VERSION "fleet-can-dataset fcs2_profile_h v2.0 (SYNTHETIC, not OEM)"

NS_ :

BS_:

BU_: ABS BCM BMS CLU ECM EPS TCM

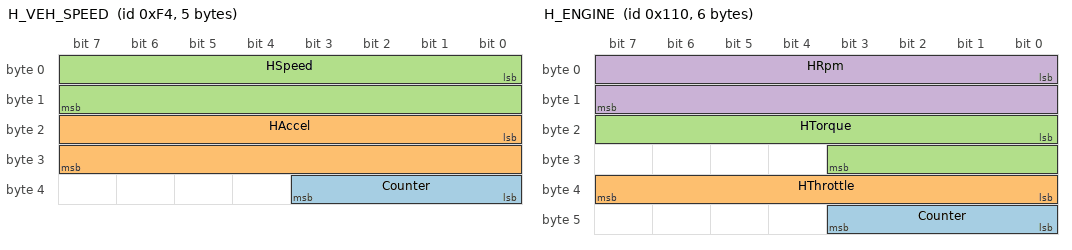
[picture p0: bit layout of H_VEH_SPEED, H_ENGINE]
BO_ 244 H_VEH_SPEED: 5 ABS
 SG_ Counter : 32|4@1+ (1,0) [0|15] "" Vector__XXX
 SG_ HAccel : 16|16@1- (0.001,0) [-32.768|32.767] "m/s^2" Vector__XXX
 SG_ HSpeed : 0|16@1+ (0.01,0) [0|655.35] "km/h" Vector__XXX

BO_ 272 H_ENGINE: 6 ECM
 SG_ Counter : 40|4@1+ (1,0) [0|15] "" Vector__XXX
 SG_ HThrottle : 32|8@1+ (0.4,0) [0|102] "%" Vector__XXX
 SG_ HTorque : 16|12@1+ (0.5,0) [0|2047.5] "Nm" Vector__XXX
 SG_ HRpm : 0|16@1+ (0.25,0) [0|16383.75] "rpm" Vector__XXX

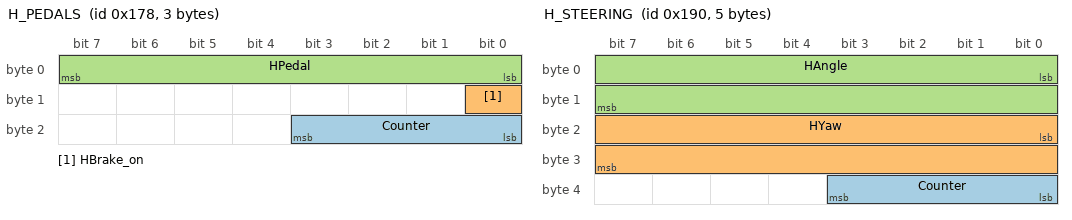
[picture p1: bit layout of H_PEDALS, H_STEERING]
BO_ 376 H_PEDALS: 3 ECM
 SG_ Counter : 16|4@1+ (1,0) [0|15] "" Vector__XXX
 SG_ HBrake_on : 8|1@1+ (1,0) [0|1] "" Vector__XXX
 SG_ HPedal : 0|8@1+ (0.4,0) [0|102] "%" Vector__XXX

BO_ 400 H_STEERING: 5 EPS
 SG_ Counter : 32|4@1+ (1,0) [0|15] "" Vector__XXX
 SG_ HYaw : 16|16@1- (0.01,0) [-327.68|327.67] "deg/s" Vector__XXX
 SG_ HAngle : 0|16@1- (0.1,0) [-3276.8|3276.7] "deg" Vector__XXX

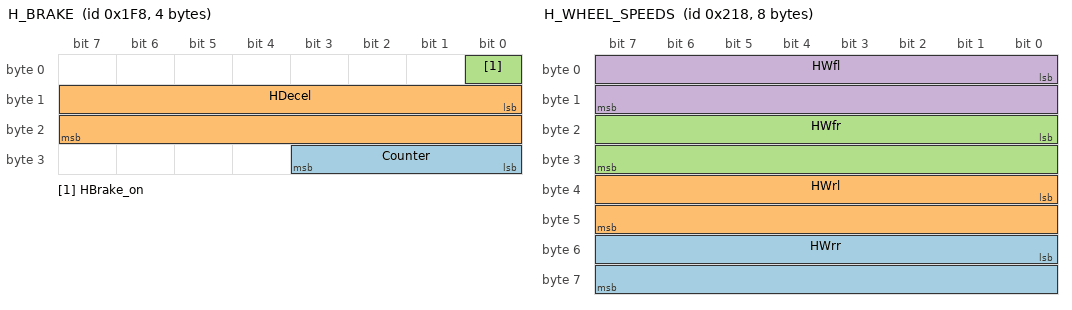
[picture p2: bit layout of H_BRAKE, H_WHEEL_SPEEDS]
BO_ 504 H_BRAKE: 4 ABS
 SG_ Counter : 24|4@1+ (1,0) [0|15] "" Vector__XXX
 SG_ HDecel : 8|16@1+ (0.001,0) [0|65.535] "m/s^2" Vector__XXX
 SG_ HBrake_on : 0|1@1+ (1,0) [0|1] "" Vector__XXX

BO_ 536 H_WHEEL_SPEEDS: 8 ABS
 SG_ HWrr : 48|16@1+ (0.01,0) [0|655.35] "km/h" Vector__XXX
 SG_ HWrl : 32|16@1+ (0.01,0) [0|655.35] "km/h" Vector__XXX
 SG_ HWfr : 16|16@1+ (0.01,0) [0|655.35] "km/h" Vector__XXX
 SG_ HWfl : 0|16@1+ (0.01,0) [0|655.35] "km/h" Vector__XXX

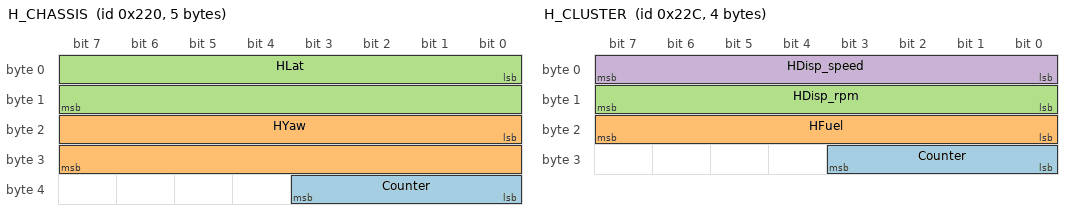
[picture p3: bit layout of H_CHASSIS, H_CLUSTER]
BO_ 544 H_CHASSIS: 5 ABS
 SG_ Counter : 32|4@1+ (1,0) [0|15] "" Vector__XXX
 SG_ HYaw : 16|16@1- (0.01,0) [-327.68|327.67] "deg/s" Vector__XXX
 SG_ HLat : 0|16@1- (0.001,0) [-32.768|32.767] "m/s^2" Vector__XXX

BO_ 556 H_CLUSTER: 4 CLU
 SG_ Counter : 24|4@1+ (1,0) [0|15] "" Vector__XXX
 SG_ HFuel : 16|8@1+ (0.4,0) [0|102] "%" Vector__XXX
 SG_ HDisp_rpm : 8|8@1+ (32,0) [0|8160] "rpm" Vector__XXX
 SG_ HDisp_speed : 0|8@1+ (1,0) [0|255] "km/h" Vector__XXX

BO_ 564 H_HEARTBEAT_ECM: 1 ECM
 SG_ Counter : 0|4@1+ (1,0) [0|15] "" Vector__XXX

BO_ 668 H_BATTERY: 3 BMS
 SG_ Counter : 16|4@1+ (1,0) [0|15] "" Vector__XXX
 SG_ HBatt : 0|16@1+ (0.001,0) [0|65.535] "V" Vector__XXX

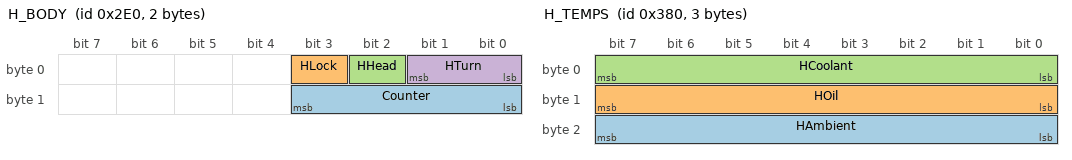
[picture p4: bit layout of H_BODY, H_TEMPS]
BO_ 736 H_BODY: 2 BCM
 SG_ Counter : 8|4@1+ (1,0) [0|15] "" Vector__XXX
 SG_ HLock : 3|1@1+ (1,0) [0|1] "" Vector__XXX
 SG_ HHead : 2|1@1+ (1,0) [0|1] "" Vector__XXX
 SG_ HTurn : 0|2@1+ (1,0) [0|3] "" Vector__XXX

BO_ 792 H_HEARTBEAT_BCM: 1 BCM
 SG_ Counter : 0|4@1+ (1,0) [0|15] "" Vector__XXX

BO_ 804 H_TRANSMISSION: 2 TCM
 SG_ Counter : 8|4@1+ (1,0) [0|15] "" Vector__XXX
 SG_ HGear : 0|4@1+ (1,0) [0|15] "" Vector__XXX

BO_ 820 H_TURN_LAMP: 2 BCM
 SG_ Counter : 8|4@1+ (1,0) [0|15] "" Vector__XXX
 SG_ HTurn : 0|2@1+ (1,0) [0|3] "" Vector__XXX

BO_ 888 H_FUEL_ODO: 4 CLU
 SG_ HOdo : 8|24@1+ (0.1,0) [0|1677721.5] "km" Vector__XXX
 SG_ HFuel : 0|8@1+ (0.4,0) [0|102] "%" Vector__XXX

BO_ 896 H_TEMPS: 3 ECM
 SG_ HAmbient : 16|8@1+ (0.5,-40) [-40|87.5] "C" Vector__XXX
 SG_ HOil : 8|8@1+ (1,-40) [-40|215] "C" Vector__XXX
 SG_ HCoolant : 0|8@1+ (1,-40) [-40|215] "C" Vector__XXX
